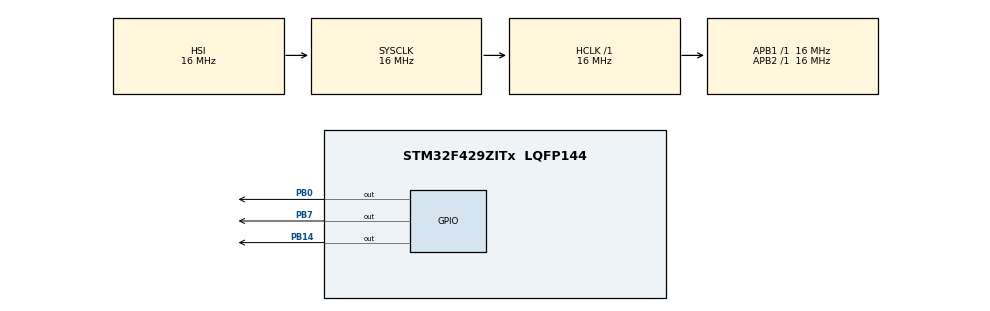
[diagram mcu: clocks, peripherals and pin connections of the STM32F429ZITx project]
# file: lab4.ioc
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FREERTOS.Tasks01=Task1,24,128,StartTask01,Default,NULL,Dynamic,NULL,NULL;Task02,8,128,StartTask02,Default,NULL,Dynamic,NULL,NULL;myTask03,8,128,StartTask03,Default,NULL,Dynamic,NULL,NULL
Mcu.Family=STM32F4
Mcu.Name=STM32F429ZITx
Mcu.Package=LQFP144
NVIC.PriorityGroup=NVIC_PRIORITYGROUP_4
PB0.Signal=GPIO_Output
PB14.Signal=GPIO_Output
PB7.Signal=GPIO_Output
ProjectManager.HeapSize=0x200
ProjectManager.StackSize=0x400
ProjectManager.TargetToolchain=STM32CubeIDE
RCC.AHBFreq_Value=16000000
RCC.APB1Freq_Value=16000000
RCC.APB2Freq_Value=16000000
RCC.CortexFreq_Value=16000000
RCC.HSE_VALUE=25000000
RCC.HSI_VALUE=16000000
RCC.LSE_VALUE=32768
RCC.SYSCLKFreq_VALUE=16000000
RCC.VCOOutputFreq_Value=192000000
VP_FREERTOS_VS_CMSIS_V2.Mode=CMSIS_V2
board=custom

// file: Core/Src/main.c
/* USER CODE BEGIN Header */
/**
  ******************************************************************************
  * @file           : main.c
  * @brief          : Main program body
  ******************************************************************************
  * @attention
  *
  * <h2><center>&copy; Copyright (c) 2020 STMicroelectronics.
  * All rights reserved.</center></h2>
  *
  * This software component is licensed by ST under BSD 3-Clause license,
  * the "License"; You may not use this file except in compliance with the
  * License. You may obtain a copy of the License at:
  *                        opensource.org/licenses/BSD-3-Clause
  *
  ******************************************************************************
  */
/* USER CODE END Header */

#include "main.h"
#include "cmsis_os.h"
#include "queue.h"
#include "stdio.h"
#include "semphr.h"

/* Definitions for Task1 */
osThreadId_t Task1Handle;
const osThreadAttr_t Task1_attributes = {
  .name = "Task1",
  .priority = (osPriority_t) osPriorityNormal,
  .stack_size = 128 * 4
};
/* Definitions for Task02 */
osThreadId_t Task02Handle;
const osThreadAttr_t Task02_attributes = {
  .name = "Task02",
  .priority = (osPriority_t) osPriorityLow,
  .stack_size = 128 * 4
};
/* Definitions for myTask03 */
osThreadId_t myTask03Handle;
const osThreadAttr_t myTask03_attributes = {
  .name = "myTask03",
  .priority = (osPriority_t) osPriorityLow,
  .stack_size = 128 * 4
};

void SystemClock_Config(void);
static void MX_GPIO_Init(void);
void StartTask01(void *argument);
void StartTask02(void *argument);
void StartTask03(void *argument);
QueueHandle_t  xQueue1;
QueueHandle_t  xQueue2;
static SemaphoreHandle_t xSemaphore = NULL;

int main(void)
{

  /* MCU Configuration--------------------------------------------------------*/

  /* Reset of all peripherals, Initializes the Flash interface and the Systick. */
  HAL_Init();

  /* Configure the system clock */
  SystemClock_Config();

  /* Initialize all configured peripherals */
  MX_GPIO_Init();

  /* Init scheduler */
  osKernelInitialize();

  HAL_GPIO_WritePin(GPIOB,GPIO_PIN_14,GPIO_PIN_RESET);
  HAL_GPIO_WritePin(GPIOB,GPIO_PIN_7,GPIO_PIN_RESET);
  HAL_GPIO_WritePin(GPIOB,GPIO_PIN_0,GPIO_PIN_RESET);
  //Create two queue capable of containing 5 int values.
  xQueue1=xQueueCreate(5,sizeof(int32_t));
  xQueue2=xQueueCreate(5,sizeof(int32_t));
  if(xQueue1 == NULL || xQueue2 == NULL)
  {
	  /* Queue was not created and must not be used. */
	  printf("Queue was not created and must not be used.\n");
  }
  else
  {
	  //create Muxtext
	  xSemaphore=xSemaphoreCreateMutex();
	  if(xSemaphore == NULL)
	  {
		  printf("Mutex was not created");
	  }
	  else
	  {

			  /* Create the thread(s) */
			  /* creation of Task1 */
			  Task1Handle = osThreadNew(StartTask01, NULL, &Task1_attributes);

			  /* creation of Task02 */
			  Task02Handle = osThreadNew(StartTask02, NULL, &Task02_attributes);

			  /* creation of myTask03 */
			  myTask03Handle = osThreadNew(StartTask03, NULL, &myTask03_attributes);

			  xSemaphoreGive(xSemaphore);
	  }
  }

  /* Start scheduler */
  osKernelStart();

  /* We should never get here as control is now taken by the scheduler */
  /* Infinite loop */
  while (1)
  {

  }
}

void SystemClock_Config(void)
{
  RCC_OscInitTypeDef RCC_OscInitStruct = {0};
  RCC_ClkInitTypeDef RCC_ClkInitStruct = {0};

  /** Configure the main internal regulator output voltage
  */
  __HAL_RCC_PWR_CLK_ENABLE();
  __HAL_PWR_VOLTAGESCALING_CONFIG(PWR_REGULATOR_VOLTAGE_SCALE3);
  /** Initializes the CPU, AHB and APB busses clocks
  */
  RCC_OscInitStruct.OscillatorType = RCC_OSCILLATORTYPE_HSI;
  RCC_OscInitStruct.HSIState = RCC_HSI_ON;
  RCC_OscInitStruct.HSICalibrationValue = RCC_HSICALIBRATION_DEFAULT;
  RCC_OscInitStruct.PLL.PLLState = RCC_PLL_NONE;
  if (HAL_RCC_OscConfig(&RCC_OscInitStruct) != HAL_OK)
  {
    Error_Handler();
  }
  /** Initializes the CPU, AHB and APB busses clocks
  */
  RCC_ClkInitStruct.ClockType = RCC_CLOCKTYPE_HCLK|RCC_CLOCKTYPE_SYSCLK
                              |RCC_CLOCKTYPE_PCLK1|RCC_CLOCKTYPE_PCLK2;
  RCC_ClkInitStruct.SYSCLKSource = RCC_SYSCLKSOURCE_HSI;
  RCC_ClkInitStruct.AHBCLKDivider = RCC_SYSCLK_DIV1;
  RCC_ClkInitStruct.APB1CLKDivider = RCC_HCLK_DIV1;
  RCC_ClkInitStruct.APB2CLKDivider = RCC_HCLK_DIV1;

  if (HAL_RCC_ClockConfig(&RCC_ClkInitStruct, FLASH_LATENCY_0) != HAL_OK)
  {
    Error_Handler();
  }
}

static void MX_GPIO_Init(void)
{
  GPIO_InitTypeDef GPIO_InitStruct = {0};

  /* GPIO Ports Clock Enable */
  __HAL_RCC_GPIOB_CLK_ENABLE();

  /*Configure GPIO pin Output Level */
  HAL_GPIO_WritePin(GPIOB, GPIO_PIN_0|GPIO_PIN_14|GPIO_PIN_7, GPIO_PIN_RESET);

  /*Configure GPIO pins : PB0 PB14 PB7 */
  GPIO_InitStruct.Pin = GPIO_PIN_0|GPIO_PIN_14|GPIO_PIN_7;
  GPIO_InitStruct.Mode = GPIO_MODE_OUTPUT_PP;
  GPIO_InitStruct.Pull = GPIO_NOPULL;
  GPIO_InitStruct.Speed = GPIO_SPEED_FREQ_LOW;
  HAL_GPIO_Init(GPIOB, &GPIO_InitStruct);

}

void StartTask01(void *argument)
{
	  int32_t counter=1; //value to write
	  BaseType_t xStatus1;
	  BaseType_t xStatus2;
	  const TickType_t xTicksToWait = pdMS_TO_TICKS( 1000 );
	  int flag=2;
	  /* USER CODE BEGIN 5 */
	  /* Infinite loop */
	  for(;;)
	  {
		//sends the “counter” value to Task 2 once per second
		xStatus1=xQueueSend( xQueue1,( void * ) &counter, xTicksToWait);
		if(xStatus1!=pdPASS)
		{
			printf("xQueue1 Failed to post the message, even after 1000 ms.");
		}

		//sends the “counter” value to Task 3 once per two seconds
		if(flag>=2)
		{
			xStatus2=xQueueSend( xQueue2,( void * ) &counter, xTicksToWait);
			if(xStatus2!=pdPASS)
			{
				printf("xQueue2 Failed to post the message, even after 1000 ms.");
			}
			flag=0;
		}

		//The incrementing of “counter” variable should be paused if the corresponding queue is full and resumed if the corresponding queue is not full.
		if(uxQueueMessagesWaiting(xQueue1)==5 || uxQueueMessagesWaiting(xQueue2)==5)
		{
			counter=counter;
		}
		else
			counter=counter+1;

		flag=flag+1;
		osDelay(1000);
	  }
	  /* USER CODE END 5 */
}

void StartTask02(void *argument)
{
  /* USER CODE BEGIN StartTask02 */
	  int32_t xReceivedValue;
	  BaseType_t xStatus;
	  const TickType_t xTicksToWait = pdMS_TO_TICKS( 1000 );
	  /* USER CODE BEGIN StartTask02 */
	  /* Infinite loop */
	  for(;;)
	  {
		if(uxQueueMessagesWaiting(xQueue1) != 0)
		{
			xStatus = xQueueReceive( xQueue1, &xReceivedValue, xTicksToWait );
			if( xStatus == pdPASS )
			 {
				xSemaphoreTake(xSemaphore, portMAX_DELAY);//Realize mutual exclusive access to resources through binary mutually exclusive semaphores, and wait forever until resources are available
				for(int32_t i=0;i<xReceivedValue;i++)
				{
					 /* After the data is successfully acquired, flip the LED2 light level, the number of flips is the number read*/
					 HAL_GPIO_TogglePin(GPIOB,GPIO_PIN_7);//led2 Flashing
					 HAL_GPIO_TogglePin(GPIOB,GPIO_PIN_0);//led1 Flashing,LED1 is used to check if LED2 flashes and conflicts with task 3
					 osDelay(550);
				}
				xSemaphoreGive(xSemaphore);//freed
				osDelay(550);//Free for a certain period of time for task 3 using LED2
			 }
			 else
			 {
				 /* Data was not received from the queue even after waiting for 1000ms. */
				 printf( "Could not receive from the queue.\r\n" );
			 }
		}
	  }
	  /* USER CODE END StartTask02 */
}

void StartTask03(void *argument)
{
  /* USER CODE BEGIN StartTask03 */
	  int32_t xReceivedValue;
	  BaseType_t xStatus;
	  const TickType_t xTicksToWait = pdMS_TO_TICKS( 1000 );
	  /* USER CODE BEGIN StartTask03 */
	  /* Infinite loop */
	  for(;;)
	  {
		if(uxQueueMessagesWaiting(xQueue2) != 0)
		{
			xStatus = xQueueReceive( xQueue2, &xReceivedValue, xTicksToWait );
			if( xStatus == pdPASS )
			 {
				xSemaphoreTake(xSemaphore, portMAX_DELAY) ;
				for(int32_t i=0;i<xReceivedValue;i++)
				{
					 /* After the data is successfully acquired, flip the LED2 light level, the number of flips is the number read*/
					 HAL_GPIO_TogglePin(GPIOB,GPIO_PIN_7);// LED2 flashing
					 HAL_GPIO_TogglePin(GPIOB,GPIO_PIN_14);//LED3 Flashing,LED3 is used to check if LED2 flashes and conflicts with task 2
					 osDelay(550);
				}
				xSemaphoreGive(xSemaphore);//freed
				osDelay(550);//Free for a certain period of time for task 2 using LED2
			 }
			 else
			 {
				 /* Data was not received from the queue even after waiting for 1000ms. */
				 printf( "Could not receive from the queue.\r\n" );
			 }
		}
	  }
  /* USER CODE END StartTask03 */
}

void Error_Handler(void)
{
}

/************************ (C) COPYRIGHT STMicroelectronics *****END OF FILE****/
